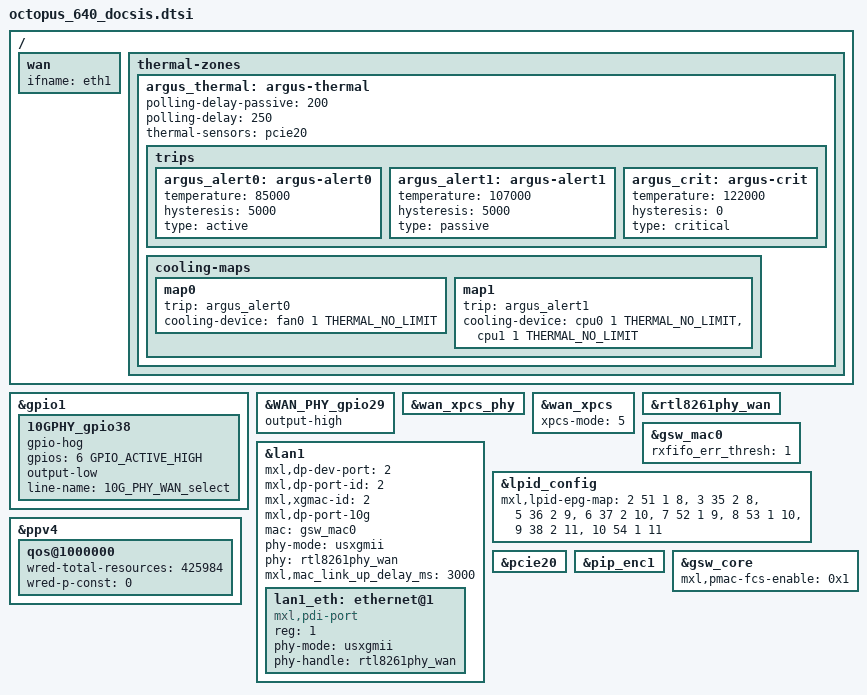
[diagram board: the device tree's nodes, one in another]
// SPDX-License-Identifier: GPL-2.0
/*
 * Copyright (C) 2024 MaxLinear, Inc.
 */

/* 10G WAN PHY as LAN */

/* Select 10G PHY WAN */
&gpio1 {
	10GPHY_gpio38 {
		gpio-hog;
		gpios = <6 GPIO_ACTIVE_HIGH>;
		output-low;
		line-name = "10G_PHY_WAN_select";
	};
};

/* Enable 10G PHY WAN */
&WAN_PHY_gpio29   {
	/delete-property/ output-low;
	output-high;
};

/ {
	wan {
		ifname = "eth1";
	};
};

/* WAN XPCS PHY */
&wan_xpcs_phy {
	status = "okay";
};

&wan_xpcs {
	status = "okay";
	xpcs-mode = <5>; /* USXGMII */
};

&rtl8261phy_wan {
	status = "okay";
};

&gsw_mac0 {
	rxfifo_err_thresh = <1>;
};

&lan1 {
	status = "okay";

	mxl,dp-dev-port = <2>;
	mxl,dp-port-id = <2>;
	mxl,xgmac-id = <2>;
	mxl,dp-port-10g;
	mac = <&gsw_mac0>;
	phy-mode = "usxgmii";
	phy = <&rtl8261phy_wan>;
	mxl,mac_link_up_delay_ms = <3000>;

	lan1_eth: ethernet@1 {
		compatible = "mxl,pdi-port";
		reg = <1>;
		phy-mode = "usxgmii";
		phy-handle = <&rtl8261phy_wan>;
	};
};

/* todo: should be moved to /sdk/feed_target_x86/intel_x86/dts/lgp_thermal.dtsi */
/ {
	thermal-zones {
		argus_thermal: argus-thermal {
			polling-delay-passive = <200>; /* milliseconds */
			polling-delay = <250>; /* milliseconds */

			thermal-sensors = <>; /* should define in *_docsis.dts */

			trips {
				argus_alert0: argus-alert0 {
					temperature = <85000>; /* millicelsius */
					hysteresis = <5000>; /* millicelsius */
					type = "active";
				};
				argus_alert1: argus-alert1 {
					temperature = <107000>; /* millicelsius */
					hysteresis = <5000>; /* millicelsius */
					type = "passive";
				};
				argus_crit: argus-crit {
					temperature = <122000>;
					hysteresis = <0>;
					type = "critical";
				};
			};

			cooling-maps {
				map0 {
					trip = <&argus_alert0>;
					cooling-device = <&fan0 1 THERMAL_NO_LIMIT>;
				};
				map1 {
					trip = <&argus_alert1>;
					cooling-device = <&cpu0 1 THERMAL_NO_LIMIT>,
							 <&cpu1 1 THERMAL_NO_LIMIT>;
				};
			};
		};
	};
};

&lpid_config {
	mxl,lpid-epg-map = <2 51 1 8>,
				<3 35 2 8>,
				<5 36 2 9>,
				<6 37 2 10>,
				<7 52 1 9>,
				<8 53 1 10>,
				<9 38 2 11>,
				<10 54 1 11>;
};

&ppv4 {
	qos@1000000 {
		wred-total-resources = <425984>;
		wred-p-const = <0>;
	};
};

&pcie20 {
	#thermal-sensor-cells = <0>;
};

&argus_thermal {
	thermal-sensors = <&pcie20>;
};

&pip_enc1 {
	status = "okay";
};

&gsw_core {
	mxl,pmac-fcs-enable = <0x1>; /* set bit 0, i.e. set FCSEN for PMAC0 */
};
